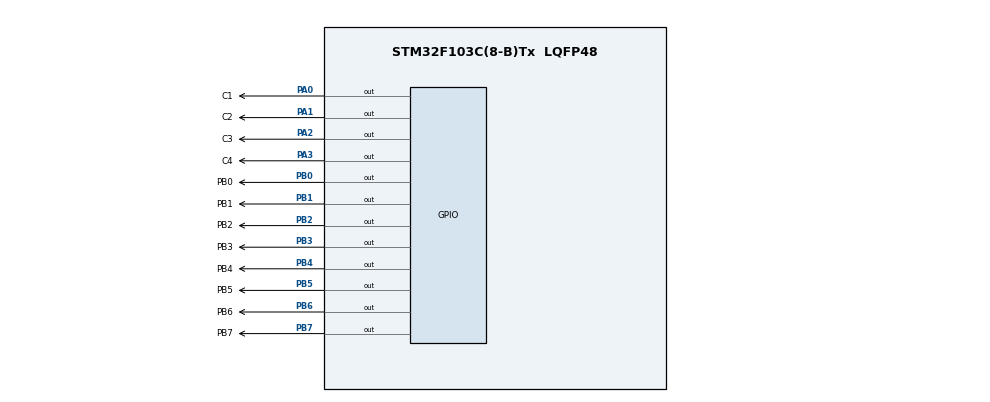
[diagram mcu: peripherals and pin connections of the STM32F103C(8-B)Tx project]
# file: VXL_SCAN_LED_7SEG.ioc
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Mcu.Family=STM32F1
Mcu.Name=STM32F103C(8-B)Tx
Mcu.Package=LQFP48
NVIC.PriorityGroup=NVIC_PRIORITYGROUP_4
PA0-WKUP.GPIO_Label=C1
PA0-WKUP.Signal=GPIO_Output
PA1.GPIO_Label=C2
PA1.Signal=GPIO_Output
PA13.Mode=Serial_Wire
PA13.Signal=SYS_JTMS-SWDIO
PA14.Mode=Serial_Wire
PA14.Signal=SYS_JTCK-SWCLK
PA2.GPIO_Label=C3
PA2.Signal=GPIO_Output
PA3.GPIO_Label=C4
PA3.Signal=GPIO_Output
PB0.GPIO_Label=PB0
PB0.Signal=GPIO_Output
PB1.GPIO_Label=PB1
PB1.Signal=GPIO_Output
PB2.GPIO_Label=PB2
PB2.Signal=GPIO_Output
PB3.GPIO_Label=PB3
PB3.Signal=GPIO_Output
PB4.GPIO_Label=PB4
PB4.Signal=GPIO_Output
PB5.GPIO_Label=PB5
PB5.Signal=GPIO_Output
PB6.GPIO_Label=PB6
PB6.Signal=GPIO_Output
PB7.GPIO_Label=PB7
PB7.Signal=GPIO_Output
ProjectManager.HeapSize=0x200
ProjectManager.StackSize=0x400
ProjectManager.TargetToolchain=MDK-ARM V5.32
RCC.APB1Freq_Value=8000000
RCC.APB2Freq_Value=8000000
board=custom

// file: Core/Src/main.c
/* USER CODE BEGIN Header */
/**
  ******************************************************************************
  * @file           : main.c
  * @brief          : Main program body
  ******************************************************************************
  * @attention
  *
  * Copyright (c) 2023 STMicroelectronics.
  * All rights reserved.
  *
  * This software is licensed under terms that can be found in the LICENSE file
  * in the root directory of this software component.
  * If no LICENSE file comes with this software, it is provided AS-IS.
  *
  ******************************************************************************
  */
/* USER CODE END Header */
#include "main.h"

/* USER CODE BEGIN PV */
const uint8_t LED[] = {0xC0,0xF9,0xA4,0xB0,0x99,0x92,0x82,0xF8,0x80,0x90,0xFF};
GPIO_TypeDef* GPIO_PORTS[] = {PB0_GPIO_Port, PB1_GPIO_Port, PB2_GPIO_Port, PB3_GPIO_Port, PB4_GPIO_Port, PB5_GPIO_Port, PB6_GPIO_Port, PB7_GPIO_Port};
uint16_t GPIO_PINS[] = {PB0_Pin, PB1_Pin, PB2_Pin, PB3_Pin, PB4_Pin, PB5_Pin, PB6_Pin, PB7_Pin};
/* USER CODE END PV */

void SystemClock_Config(void);
static void MX_GPIO_Init(void);

/* USER CODE BEGIN 0 */
void LED_display(uint8_t n){
	for(uint8_t i = 0; i<8; i++){
		HAL_GPIO_WritePin(GPIO_PORTS[i],GPIO_PINS[i],LED[n]>>i&1u);
	}
}
/* USER CODE END 0 */

int main(void)
{

  /* MCU Configuration--------------------------------------------------------*/

  /* Reset of all peripherals, Initializes the Flash interface and the Systick. */
  HAL_Init();

  /* Configure the system clock */
  SystemClock_Config();

  /* Initialize all configured peripherals */
  MX_GPIO_Init();

  /* Infinite loop */
  while (1)
  {
		for( uint8_t i = 0;i < 10; i++){
			LED_display(i);
			HAL_GPIO_WritePin(C4_GPIO_Port,C4_Pin,1);
			HAL_Delay(200);
		}
  }
}

void SystemClock_Config(void)
{
  RCC_OscInitTypeDef RCC_OscInitStruct = {0};
  RCC_ClkInitTypeDef RCC_ClkInitStruct = {0};

  /** Initializes the RCC Oscillators according to the specified parameters
  * in the RCC_OscInitTypeDef structure.
  */
  RCC_OscInitStruct.OscillatorType = RCC_OSCILLATORTYPE_HSI;
  RCC_OscInitStruct.HSIState = RCC_HSI_ON;
  RCC_OscInitStruct.HSICalibrationValue = RCC_HSICALIBRATION_DEFAULT;
  RCC_OscInitStruct.PLL.PLLState = RCC_PLL_NONE;
  if (HAL_RCC_OscConfig(&RCC_OscInitStruct) != HAL_OK)
  {
    Error_Handler();
  }

  /** Initializes the CPU, AHB and APB buses clocks
  */
  RCC_ClkInitStruct.ClockType = RCC_CLOCKTYPE_HCLK|RCC_CLOCKTYPE_SYSCLK
                              |RCC_CLOCKTYPE_PCLK1|RCC_CLOCKTYPE_PCLK2;
  RCC_ClkInitStruct.SYSCLKSource = RCC_SYSCLKSOURCE_HSI;
  RCC_ClkInitStruct.AHBCLKDivider = RCC_SYSCLK_DIV1;
  RCC_ClkInitStruct.APB1CLKDivider = RCC_HCLK_DIV1;
  RCC_ClkInitStruct.APB2CLKDivider = RCC_HCLK_DIV1;

  if (HAL_RCC_ClockConfig(&RCC_ClkInitStruct, FLASH_LATENCY_0) != HAL_OK)
  {
    Error_Handler();
  }
}

static void MX_GPIO_Init(void)
{
  GPIO_InitTypeDef GPIO_InitStruct = {0};

  /* GPIO Ports Clock Enable */
  __HAL_RCC_GPIOC_CLK_ENABLE();
  __HAL_RCC_GPIOD_CLK_ENABLE();
  __HAL_RCC_GPIOA_CLK_ENABLE();
  __HAL_RCC_GPIOB_CLK_ENABLE();

  /*Configure GPIO pin Output Level */
  HAL_GPIO_WritePin(GPIOA, C1_Pin|C2_Pin|C3_Pin|C4_Pin, GPIO_PIN_RESET);

  /*Configure GPIO pin Output Level */
  HAL_GPIO_WritePin(GPIOB, PB0_Pin|PB1_Pin|PB2_Pin|PB3_Pin
                          |PB4_Pin|PB5_Pin|PB6_Pin|PB7_Pin, GPIO_PIN_RESET);

  /*Configure GPIO pins : PC13 PC14 PC15 */
  GPIO_InitStruct.Pin = GPIO_PIN_13|GPIO_PIN_14|GPIO_PIN_15;
  GPIO_InitStruct.Mode = GPIO_MODE_ANALOG;
  HAL_GPIO_Init(GPIOC, &GPIO_InitStruct);

  /*Configure GPIO pins : PD0 PD1 */
  GPIO_InitStruct.Pin = GPIO_PIN_0|GPIO_PIN_1;
  GPIO_InitStruct.Mode = GPIO_MODE_ANALOG;
  HAL_GPIO_Init(GPIOD, &GPIO_InitStruct);

  /*Configure GPIO pins : C1_Pin C2_Pin C3_Pin C4_Pin */
  GPIO_InitStruct.Pin = C1_Pin|C2_Pin|C3_Pin|C4_Pin;
  GPIO_InitStruct.Mode = GPIO_MODE_OUTPUT_PP;
  GPIO_InitStruct.Pull = GPIO_NOPULL;
  GPIO_InitStruct.Speed = GPIO_SPEED_FREQ_LOW;
  HAL_GPIO_Init(GPIOA, &GPIO_InitStruct);

  /*Configure GPIO pins : PA4 PA5 PA6 PA7
                           PA8 PA9 PA10 PA11
                           PA12 PA15 */
  GPIO_InitStruct.Pin = GPIO_PIN_4|GPIO_PIN_5|GPIO_PIN_6|GPIO_PIN_7
                          |GPIO_PIN_8|GPIO_PIN_9|GPIO_PIN_10|GPIO_PIN_11
                          |GPIO_PIN_12|GPIO_PIN_15;
  GPIO_InitStruct.Mode = GPIO_MODE_ANALOG;
  HAL_GPIO_Init(GPIOA, &GPIO_InitStruct);

  /*Configure GPIO pins : PB0_Pin PB1_Pin PB2_Pin PB3_Pin
                           PB4_Pin PB5_Pin PB6_Pin PB7_Pin */
  GPIO_InitStruct.Pin = PB0_Pin|PB1_Pin|PB2_Pin|PB3_Pin
                          |PB4_Pin|PB5_Pin|PB6_Pin|PB7_Pin;
  GPIO_InitStruct.Mode = GPIO_MODE_OUTPUT_PP;
  GPIO_InitStruct.Pull = GPIO_NOPULL;
  GPIO_InitStruct.Speed = GPIO_SPEED_FREQ_LOW;
  HAL_GPIO_Init(GPIOB, &GPIO_InitStruct);

  /*Configure GPIO pins : PB10 PB11 PB12 PB13
                           PB14 PB15 PB8 PB9 */
  GPIO_InitStruct.Pin = GPIO_PIN_10|GPIO_PIN_11|GPIO_PIN_12|GPIO_PIN_13
                          |GPIO_PIN_14|GPIO_PIN_15|GPIO_PIN_8|GPIO_PIN_9;
  GPIO_InitStruct.Mode = GPIO_MODE_ANALOG;
  HAL_GPIO_Init(GPIOB, &GPIO_InitStruct);

  /*Configure peripheral I/O remapping */
  __HAL_AFIO_REMAP_PD01_ENABLE();

}

void Error_Handler(void)
{
  __disable_irq();
  while (1)
  {
  }
}
